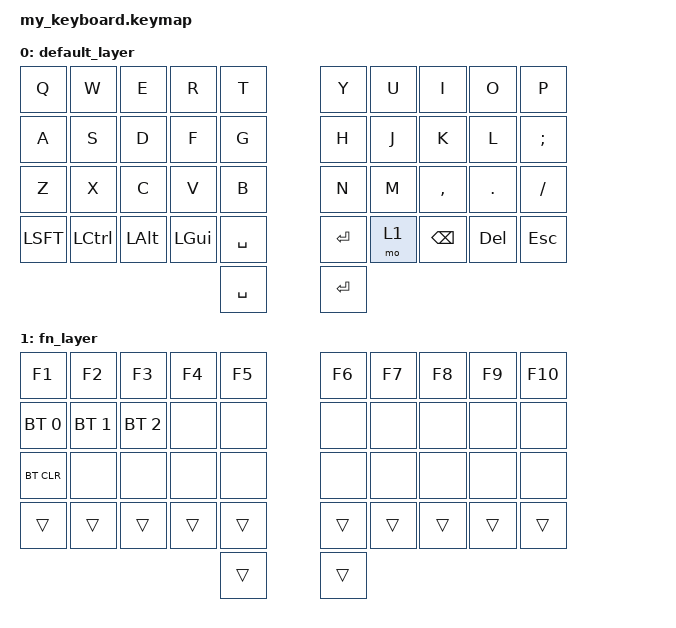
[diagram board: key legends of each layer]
#include <behaviors.dtsi>
#include <dt-bindings/zmk/keys.h>
#include <dt-bindings/zmk/bt.h>

/ {
    keymap {
        compatible = "zmk,keymap";

        default_layer {
            bindings = 
            // LEFT (21 keys)                              RIGHT (21 keys)
            &kp Q  &kp W  &kp E  &kp R  &kp T             &kp Y  &kp U  &kp I     &kp O    &kp P
            &kp A  &kp S  &kp D  &kp F  &kp G             &kp H  &kp J  &kp K     &kp L    &kp SEMI
            &kp Z  &kp X  &kp C  &kp V  &kp B             &kp N  &kp M  &kp COMMA &kp DOT  &kp FSLH
            &kp LSFT &kp LCTL &kp LALT &kp LGUI &kp SPC   &kp RET &mo 1 &kp BSPC &kp DEL &kp ESC
                                         &kp SPACE         &kp RET
            >;
        };

        fn_layer {
            bindings = 
            &kp F1       &kp F2       &kp F3       &kp F4 &kp F5    &kp F6 &kp F7 &kp F8 &kp F9  &kp F10
            &bt BT_SEL 0 &bt BT_SEL 1 &bt BT_SEL 2 &none &none     &none  &none  &none  &none   &none
            &bt BT_CLR   &none        &none        &none  &none     &none  &none  &none  &none   &none
            &trans       &trans       &trans       &trans &trans    &trans &trans &trans &trans  &trans
                                                   &trans           &trans
            >;
        };
    };
};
